# MDR1986VK01 register map
File version: 1.0.2
Registers are 32-bit, read-write, no defined reset value unless marked. A register's access mark holds for its fields unless they carry their own. Offsets are from the block's base; [hi:lo] are bit positions; {n}, {i} and the like mark numbered series; 'fields as' and 'values as' point back to an identical list.

## MDR_CAP0 — MDR_CAP0 description
Base 0x40098000
Same registers: MDR_CAP1 0x40099000, MDR_CAP2 0x4009A000, MDR_CAP3 0x4009B000
0x00 TSCTR — TSCTR description
0x04 CTRPHS — CTRPHS description
{0x4+4i} CAP{i} (i=1..4) — CAP{i} description
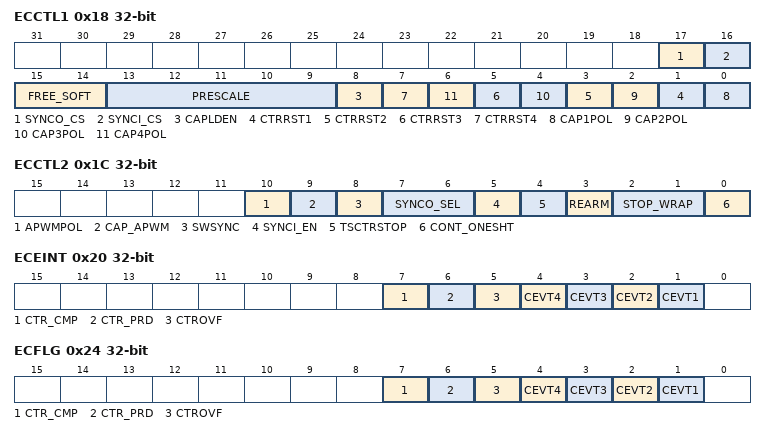
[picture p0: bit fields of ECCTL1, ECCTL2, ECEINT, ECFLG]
0x18 ECCTL1 — ECCTL1 description
  [17] SYNCO_CS — SYNCO_CS description
  [16] SYNCI_CS — SYNCI_CS description
  [15:14] FREE_SOFT — FREE_SOFT description
  [13:9] PRESCALE — PRESCALE description
  [8] CAPLDEN — CAPLDEN description
  [2n-1] CTRRST{n} (n=1..4) — CTRRST{n} description
  [2n-2] CAP{n}POL (n=1..4) — CAP{n}POL description
0x1C ECCTL2 — ECCTL2 description
  [10] APWMPOL — APWMPOL description
  [9] CAP_APWM — CAP_APWM description
  [8] SWSYNC — SWSYNC description
  [7:6] SYNCO_SEL — SYNCO_SEL description
  [5] SYNCI_EN — SYNCI_EN description
  [4] TSCTRSTOP — TSCTRSTOP description
  [3] REARM — REARM description
  [2:1] STOP_WRAP — STOP_WRAP description
  [0] CONT_ONESHT — CONT_ONESHT description
0x20 ECEINT — ECEINT description
  [7] CTR_CMP — CTR_CMP description
  [6] CTR_PRD — CTR_PRD description
  [5] CTROVF — CTROVF description
  [n] CEVT{n} (n=1..4) — CEVT{n} description
0x24 ECFLG — ECFLG description
  fields as ECEINT
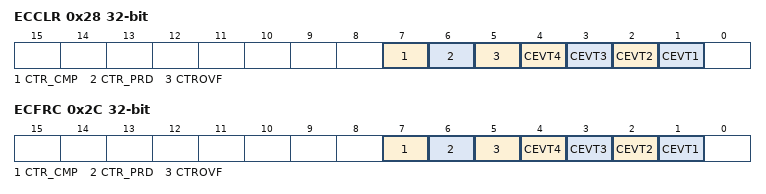
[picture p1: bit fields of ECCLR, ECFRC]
0x28 ECCLR — ECCLR description
  fields as ECEINT
0x2C ECFRC — ECFRC description
  fields as ECEINT

## MDR_QEP0 — MDR_QEP0 description
Base 0x4009C000
Same registers: MDR_QEP1 0x4009D000
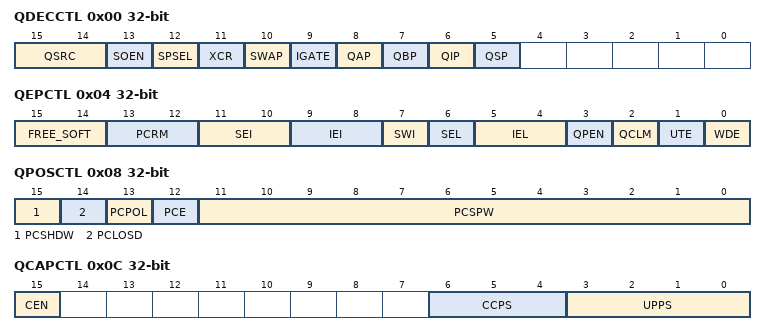
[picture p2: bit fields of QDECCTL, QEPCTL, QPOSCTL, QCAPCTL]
0x00 QDECCTL — QDECCTL description
  [15:14] QSRC — QSRC description
  [13] SOEN — SOEN description
  [12] SPSEL — SPSEL description
  [11] XCR — XCR description
  [10] SWAP — SWAP description
  [9] IGATE — IGATE description
  [8] QAP — QAP description
  [7] QBP — QBP description
  [6] QIP — QIP description
  [5] QSP — QSP description
0x04 QEPCTL — QEPCTL description
  [15:14] FREE_SOFT — FREE_SOFT description
  [13:12] PCRM — PCRM description
  [11:10] SEI — SEI description
  [9:8] IEI — IEI description
  [7] SWI — SWI description
  [6] SEL — SEL description
  [5:4] IEL — IEL description
  [3] QPEN — QPEN description
  [2] QCLM — QCLM description
  [1] UTE — UTE description
  [0] WDE — WDE description
0x08 QPOSCTL — QPOSCTL description
  [15] PCSHDW — PCSHDW description
  [14] PCLOSD — PCLOSD description
  [13] PCPOL — PCPOL description
  [12] PCE — PCE description
  [11:0] PCSPW — PCSPW description
0x0C QCAPCTL — QCAPCTL description
  [15] CEN — CEN description
  [6:4] CCPS — CCPS description
  [3:0] UPPS — UPPS description
0x10 QPOSCNT — QPOSCNT description
0x14 QPOSINIT — QPOSINIT description
0x18 QPOSMAX — QPOSMAX description
0x1C QPOSCMP — QPOSCMP description
0x20 QPOSILAT — QPOSILAT description
0x24 QPOSSLAT — QPOSSLAT description
0x28 QPOSLAT — QPOSLAT description
0x2C QUTMR — QUTMR description
0x30 QUPRD — QUPRD description
0x34 QWDTMR — QWDTMR description
  [15:0] QWDTMR
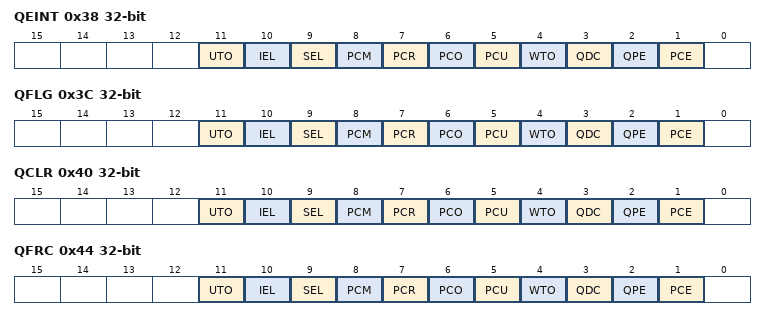
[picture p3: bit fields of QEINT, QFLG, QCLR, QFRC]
0x38 QEINT — QEINT description
  [11] UTO — UTO description
  [10] IEL — IEL description
  [9] SEL — SEL description
  [8] PCM — PCM description
  [7] PCR — PCR description
  [6] PCO — PCO description
  [5] PCU — PCU description
  [4] WTO — WTO description
  [3] QDC — QDC description
  [2] QPE — QPE description
  [1] PCE — PCE description
0x3C QFLG — QFLG description
  fields as QEINT
0x40 QCLR — QCLR description
  fields as QEINT
0x44 QFRC — QFRC description
  fields as QEINT
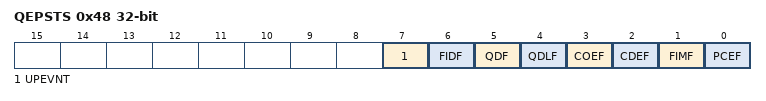
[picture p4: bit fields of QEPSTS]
0x48 QEPSTS — QEPSTS description
  [7] UPEVNT — UPEVNT description
  [6] FIDF — FIDF description
  [5] QDF — QDF description
  [4] QDLF — QDLF description
  [3] COEF — COEF description
  [2] CDEF — CDEF description
  [1] FIMF — FIMF description
  [0] PCEF — PCEF description
0x4C QWDPRD — QWDPRD description
  [15:0] QWDPRD
0x50 QCTMR — QCTMR description
  [15:0] QCTMR
{0x50+4i} QCTMR{i} (i=1..4) — QCTMR{i} description
  [15:0] QCTMR{i}
0x64 QCPRD — QCPRD description
  [15:0] QCTMR4 — QCTMR4 description
0x68 QCTMRLAT — QCTMRLAT description
  [15:0] QCTMRLAT
0x6C QCPRDLAT — QCPRDLAT description
  [15:0] QCPRDLAT
